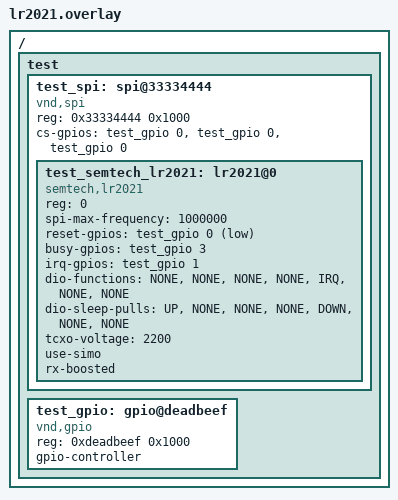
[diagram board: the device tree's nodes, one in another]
/*
 * Copyright (c) 2026 MASSDRIVER EI (massdriver.space)
 * SPDX-License-Identifier: Apache-2.0
 */

/ {
	test {
		#address-cells = <1>;
		#size-cells = <1>;

		test_spi: spi@33334444 {
			compatible = "vnd,spi";
			reg = <0x33334444 0x1000>;
			#address-cells = <1>;
			#size-cells = <0>;

			cs-gpios = <&test_gpio 0 0>,
				   <&test_gpio 0 0>,
				   <&test_gpio 0 0>;
			status = "okay";

			test_semtech_lr2021: lr2021@0 {
				compatible = "semtech,lr2021";
				reg = <0>;
				spi-max-frequency = <1000000>;
				reset-gpios = <&test_gpio 0 GPIO_ACTIVE_LOW>;
				busy-gpios = <&test_gpio 3 GPIO_ACTIVE_HIGH>;
				irq-gpios = <&test_gpio 1 (GPIO_PULL_DOWN | GPIO_ACTIVE_HIGH)>;
				dio-functions = "NONE", "NONE", "NONE", "NONE", "IRQ", "NONE",
						"NONE";
				dio-sleep-pulls = "UP", "NONE", "NONE", "NONE", "DOWN", "NONE",
						  "NONE";
				tcxo-voltage = <2200>;
				use-simo;
				rx-boosted;
				status = "okay";
			};
		};

		test_gpio: gpio@deadbeef {
			compatible = "vnd,gpio";
			reg = <0xdeadbeef 0x1000>;
			gpio-controller;
			#gpio-cells = <0x2>;
			status = "okay";
		};
	};
};
